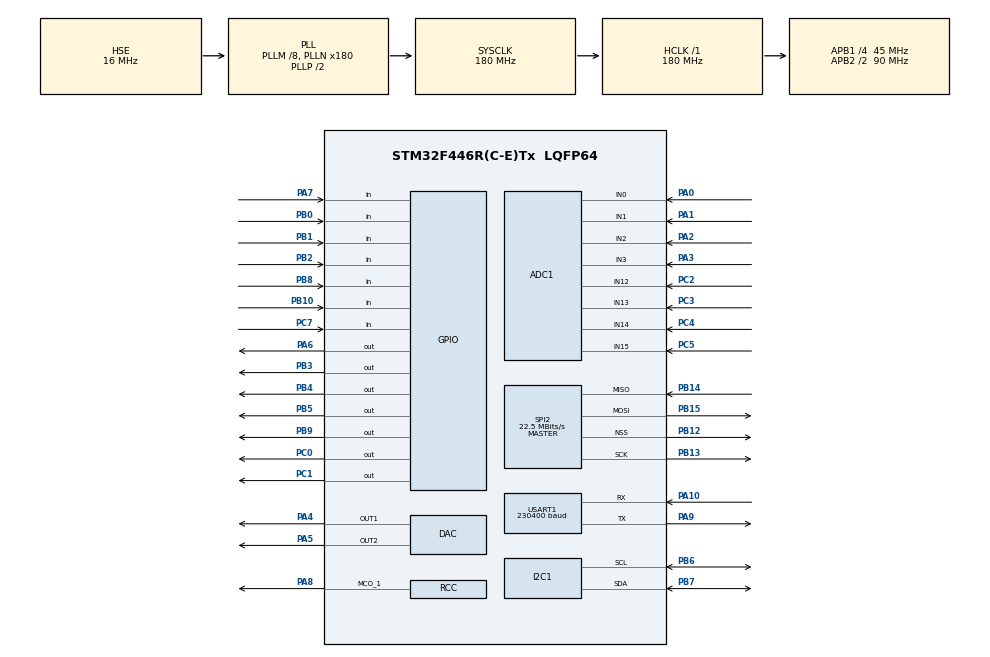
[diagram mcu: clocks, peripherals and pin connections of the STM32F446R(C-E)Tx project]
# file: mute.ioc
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ADC1.Channel-0\#ChannelRegularConversion=ADC_CHANNEL_0
ADC1.Channel-1\#ChannelRegularConversion=ADC_CHANNEL_1
ADC1.Channel-2\#ChannelRegularConversion=ADC_CHANNEL_2
ADC1.Channel-3\#ChannelRegularConversion=ADC_CHANNEL_3
ADC1.Channel-4\#ChannelRegularConversion=ADC_CHANNEL_12
ADC1.Channel-5\#ChannelRegularConversion=ADC_CHANNEL_13
ADC1.Channel-6\#ChannelRegularConversion=ADC_CHANNEL_14
ADC1.Channel-7\#ChannelRegularConversion=ADC_CHANNEL_15
ADC1.ClockPrescaler=ADC_CLOCK_SYNC_PCLK_DIV4
ADC1.ContinuousConvMode=ENABLE
ADC1.DMAContinuousRequests=ENABLE
ADC1.DiscontinuousConvMode=DISABLE
ADC1.EOCSelection=ADC_EOC_SEQ_CONV
ADC1.NbrOfConversion=8
ADC1.NbrOfConversionFlag=1
ADC1.Rank-0\#ChannelRegularConversion=1
ADC1.Rank-1\#ChannelRegularConversion=2
ADC1.Rank-2\#ChannelRegularConversion=3
ADC1.Rank-3\#ChannelRegularConversion=4
ADC1.Rank-4\#ChannelRegularConversion=5
ADC1.Rank-5\#ChannelRegularConversion=6
ADC1.Rank-6\#ChannelRegularConversion=7
ADC1.Rank-7\#ChannelRegularConversion=8
ADC1.SamplingTime-0\#ChannelRegularConversion=ADC_SAMPLETIME_144CYCLES
ADC1.SamplingTime-1\#ChannelRegularConversion=ADC_SAMPLETIME_144CYCLES
ADC1.SamplingTime-2\#ChannelRegularConversion=ADC_SAMPLETIME_144CYCLES
ADC1.SamplingTime-3\#ChannelRegularConversion=ADC_SAMPLETIME_144CYCLES
ADC1.SamplingTime-4\#ChannelRegularConversion=ADC_SAMPLETIME_144CYCLES
ADC1.SamplingTime-5\#ChannelRegularConversion=ADC_SAMPLETIME_144CYCLES
ADC1.SamplingTime-6\#ChannelRegularConversion=ADC_SAMPLETIME_144CYCLES
ADC1.SamplingTime-7\#ChannelRegularConversion=ADC_SAMPLETIME_144CYCLES
ADC1.ScanConvMode=ENABLE
ADC1.master=1
AwesomeAudioApparatus.Demiurge.0.4.4.AudioJjDemiurge=true
AwesomeAudioApparatus.Demiurge.0.4.4.BoardOoSupportJjDemiurge1JjRevG=true
AwesomeAudioApparatus.Demiurge.0.4.4.DeviceJjApplication=SDK
Dma.ADC1.0.Direction=DMA_PERIPH_TO_MEMORY
Dma.ADC1.0.FIFOMode=DMA_FIFOMODE_DISABLE
Dma.ADC1.0.Instance=DMA2_Stream0
Dma.ADC1.0.MemDataAlignment=DMA_MDATAALIGN_HALFWORD
Dma.ADC1.0.MemInc=DMA_MINC_ENABLE
Dma.ADC1.0.Mode=DMA_CIRCULAR
Dma.ADC1.0.PeriphDataAlignment=DMA_PDATAALIGN_HALFWORD
Dma.ADC1.0.PeriphInc=DMA_PINC_DISABLE
Dma.ADC1.0.Priority=DMA_PRIORITY_MEDIUM
Dma.I2C1_TX.1.Direction=DMA_MEMORY_TO_PERIPH
Dma.I2C1_TX.1.FIFOMode=DMA_FIFOMODE_DISABLE
Dma.I2C1_TX.1.Instance=DMA1_Stream6
Dma.I2C1_TX.1.MemDataAlignment=DMA_MDATAALIGN_BYTE
Dma.I2C1_TX.1.MemInc=DMA_MINC_ENABLE
Dma.I2C1_TX.1.Mode=DMA_NORMAL
Dma.I2C1_TX.1.PeriphDataAlignment=DMA_PDATAALIGN_BYTE
Dma.I2C1_TX.1.PeriphInc=DMA_PINC_DISABLE
Dma.I2C1_TX.1.Priority=DMA_PRIORITY_LOW
Dma.Request0=ADC1
Dma.Request1=I2C1_TX
Mcu.Family=STM32F4
Mcu.Name=STM32F446R(C-E)Tx
Mcu.Package=LQFP64
NVIC.DMA1_Stream6_IRQn=true\:0\:0\:false\:false\:true\:true\:true\:true
NVIC.I2C1_EV_IRQn=true\:0\:0\:false\:false\:true\:true\:true\:true
NVIC.PriorityGroup=NVIC_PRIORITYGROUP_4
NVIC.TIM3_IRQn=true\:15\:0\:true\:false\:true\:true\:true\:true
PA0-WKUP.Signal=ADCx_IN0
PA1.Signal=ADCx_IN1
PA10.Mode=Asynchronous
PA10.Signal=USART1_RX
PA11.Signal=USB_OTG_FS_DM
PA12.Signal=USB_OTG_FS_DP
PA13.Mode=Serial_Wire
PA13.Signal=SYS_JTMS-SWDIO
PA14.Mode=Serial_Wire
PA14.Signal=SYS_JTCK-SWCLK
PA2.Signal=ADCx_IN2
PA3.Signal=ADCx_IN3
PA4.Signal=COMP_DAC1_group
PA5.Signal=COMP_DAC2_group
PA6.Signal=GPIO_Output
PA7.Signal=GPIO_Input
PA8.Mode=Clock-out-1
PA8.Signal=RCC_MCO_1
PA9.Mode=Asynchronous
PA9.Signal=USART1_TX
PB0.Signal=GPIO_Input
PB1.Signal=GPIO_Input
PB10.Signal=GPIO_Input
PB12.Mode=NSS_Signal_Hard_Output
PB12.Signal=SPI2_NSS
PB13.Mode=Full_Duplex_Master
PB13.Signal=SPI2_SCK
PB14.Mode=Full_Duplex_Master
PB14.Signal=SPI2_MISO
PB15.Mode=Full_Duplex_Master
PB15.Signal=SPI2_MOSI
PB2.Signal=GPIO_Input
PB3.Signal=GPIO_Output
PB4.Signal=GPIO_Output
PB5.Signal=GPIO_Output
PB6.Mode=I2C
PB6.Signal=I2C1_SCL
PB7.Mode=I2C
PB7.Signal=I2C1_SDA
PB8.Signal=GPIO_Input
PB9.PinState=GPIO_PIN_RESET
PB9.Signal=GPIO_Output
PC0.Signal=GPIO_Output
PC1.Signal=GPIO_Output
PC10.Signal=SDIO_D2
PC11.Signal=SDIO_D3
PC12.Signal=SDIO_CK
PC2.Signal=ADCx_IN12
PC3.Signal=ADCx_IN13
PC4.Signal=ADCx_IN14
PC5.Signal=ADCx_IN15
PC7.Signal=GPIO_Input
PC8.Signal=SDIO_D0
PC9.Signal=SDIO_D1
PD2.Signal=SDIO_CMD
PH0-OSC_IN.Mode=HSE-External-Oscillator
PH0-OSC_IN.Signal=RCC_OSC_IN
PH1-OSC_OUT.Mode=HSE-External-Oscillator
PH1-OSC_OUT.Signal=RCC_OSC_OUT
ProjectManager.HeapSize=0x200
ProjectManager.StackSize=0x400
ProjectManager.TargetToolchain=STM32CubeIDE
RCC.AHBFreq_Value=180000000
RCC.APB1CLKDivider=RCC_HCLK_DIV4
RCC.APB1Freq_Value=45000000
RCC.APB1TimFreq_Value=90000000
RCC.APB2CLKDivider=RCC_HCLK_DIV2
RCC.APB2Freq_Value=90000000
RCC.APB2TimFreq_Value=180000000
RCC.CortexFreq_Value=180000000
RCC.HCLKFreq_Value=180000000
RCC.HSE_Timout=200
RCC.HSE_VALUE=16000000
RCC.PLLM=8
RCC.PLLN=180
RCC.PLLQ=8
RCC.PLLSourceVirtual=RCC_PLLSOURCE_HSE
RCC.RCC_MCO1Source=RCC_MCO1SOURCE_HSE
RCC.SYSCLKFreq_VALUE=180000000
RCC.SYSCLKSource=RCC_SYSCLKSOURCE_PLLCLK
RCC.USBFreq_Value=45000000
RCC.VCOOutputFreq_Value=360000000
SH.ADCx_IN0.0=ADC1_IN0,IN0
SH.ADCx_IN1.0=ADC1_IN1,IN1
SH.ADCx_IN12.0=ADC1_IN12,IN12
SH.ADCx_IN13.0=ADC1_IN13,IN13
SH.ADCx_IN14.0=ADC1_IN14,IN14
SH.ADCx_IN15.0=ADC1_IN15,IN15
SH.ADCx_IN2.0=ADC1_IN2,IN2
SH.ADCx_IN3.0=ADC1_IN3,IN3
SH.COMP_DAC1_group.0=DAC_OUT1,DAC_OUT1
SH.COMP_DAC2_group.0=DAC_OUT2,DAC_OUT2
SPI2.BaudRatePrescaler=SPI_BAUDRATEPRESCALER_2
SPI2.CalculateBaudRate=22.5 MBits/s
SPI2.Direction=SPI_DIRECTION_2LINES
SPI2.Mode=SPI_MODE_MASTER
SPI2.VirtualNSS=VM_NSSHARD
SPI2.VirtualType=VM_MASTER
TIM3.AutoReloadPreload=TIM_AUTORELOAD_PRELOAD_ENABLE
TIM3.CounterMode=TIM_COUNTERMODE_DOWN
TIM3.Period=3750
USART1.BaudRate=230400
USART1.VirtualMode=VM_ASYNC
VP_AwesomeAudioApparatus.Demiurge_VS_AudioJjDemiurge_0.4.1_0.4.4.Mode=AudioJjDemiurge
VP_AwesomeAudioApparatus.Demiurge_VS_BoardOoSupportJjDemiurge1_0.4.1_0.4.4.Mode=BoardOoSupportJjDemiurge1
VP_AwesomeAudioApparatus.Demiurge_VS_DeviceJjApplication_0.4.0_0.4.4.Mode=DeviceJjApplication
VP_TIM3_VS_ClockSourceINT.Mode=Internal
board=custom

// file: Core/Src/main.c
/* USER CODE BEGIN Header */
/*
  Copyright 2019-2022, Awesome Audio Apparatus.

Licensed under the Apache License, Version 2.0 (the "License");
you may not use this file except in compliance with the License.
You may obtain a copy of the License at

      https://www.apache.org/licenses/LICENSE-2.0

Unless required by applicable law or agreed to in writing, software
distributed under the License is distributed on an "AS IS" BASIS,
WITHOUT WARRANTIES OR CONDITIONS OF ANY KIND, either express or implied.
See the License for the specific language governing permissions and
      limitations under the License.
*/
/* USER CODE END Header */
#include "main.h"

/* USER CODE BEGIN Includes */
#include "demiurge.h"
/* USER CODE END Includes */

ADC_HandleTypeDef hadc1;
DMA_HandleTypeDef hdma_adc1;

DAC_HandleTypeDef hdac;

I2C_HandleTypeDef hi2c1;
DMA_HandleTypeDef hdma_i2c1_tx;

SPI_HandleTypeDef hspi2;

TIM_HandleTypeDef htim3;

UART_HandleTypeDef huart1;

void SystemClock_Config(void);
static void MX_GPIO_Init(void);
static void MX_DMA_Init(void);
static void MX_ADC1_Init(void);
static void MX_DAC_Init(void);
static void MX_TIM3_Init(void);
static void MX_I2C1_Init(void);
static void MX_SPI2_Init(void);
static void MX_USART1_UART_Init(void);

int main(void)
{

  /* MCU Configuration--------------------------------------------------------*/

  /* Reset of all peripherals, Initializes the Flash interface and the Systick. */
  HAL_Init();

  /* Configure the system clock */
  SystemClock_Config();

  /* Initialize all configured peripherals */
  MX_GPIO_Init();
  MX_DMA_Init();
  MX_ADC1_Init();
  MX_DAC_Init();
  MX_TIM3_Init();
  MX_I2C1_Init();
  MX_SPI2_Init();
  MX_USART1_UART_Init();
  MX_User_Init();

  /* Infinite loop */
  while (1)
  {

  MX_User_Process();
  }
}

void SystemClock_Config(void)
{
  RCC_OscInitTypeDef RCC_OscInitStruct = {0};
  RCC_ClkInitTypeDef RCC_ClkInitStruct = {0};

  /** Configure the main internal regulator output voltage
  */
  __HAL_RCC_PWR_CLK_ENABLE();
  __HAL_PWR_VOLTAGESCALING_CONFIG(PWR_REGULATOR_VOLTAGE_SCALE1);

  /** Initializes the RCC Oscillators according to the specified parameters
  * in the RCC_OscInitTypeDef structure.
  */
  RCC_OscInitStruct.OscillatorType = RCC_OSCILLATORTYPE_HSE;
  RCC_OscInitStruct.HSEState = RCC_HSE_ON;
  RCC_OscInitStruct.PLL.PLLState = RCC_PLL_ON;
  RCC_OscInitStruct.PLL.PLLSource = RCC_PLLSOURCE_HSE;
  RCC_OscInitStruct.PLL.PLLM = 8;
  RCC_OscInitStruct.PLL.PLLN = 180;
  RCC_OscInitStruct.PLL.PLLP = RCC_PLLP_DIV2;
  RCC_OscInitStruct.PLL.PLLQ = 8;
  RCC_OscInitStruct.PLL.PLLR = 2;
  if (HAL_RCC_OscConfig(&RCC_OscInitStruct) != HAL_OK)
  {
    Error_Handler();
  }

  /** Activate the Over-Drive mode
  */
  if (HAL_PWREx_EnableOverDrive() != HAL_OK)
  {
    Error_Handler();
  }

  /** Initializes the CPU, AHB and APB buses clocks
  */
  RCC_ClkInitStruct.ClockType = RCC_CLOCKTYPE_HCLK|RCC_CLOCKTYPE_SYSCLK
                              |RCC_CLOCKTYPE_PCLK1|RCC_CLOCKTYPE_PCLK2;
  RCC_ClkInitStruct.SYSCLKSource = RCC_SYSCLKSOURCE_PLLCLK;
  RCC_ClkInitStruct.AHBCLKDivider = RCC_SYSCLK_DIV1;
  RCC_ClkInitStruct.APB1CLKDivider = RCC_HCLK_DIV4;
  RCC_ClkInitStruct.APB2CLKDivider = RCC_HCLK_DIV2;

  if (HAL_RCC_ClockConfig(&RCC_ClkInitStruct, FLASH_LATENCY_5) != HAL_OK)
  {
    Error_Handler();
  }
  HAL_RCC_MCOConfig(RCC_MCO1, RCC_MCO1SOURCE_HSE, RCC_MCODIV_1);
}

static void MX_ADC1_Init(void)
{

  ADC_ChannelConfTypeDef sConfig = {0};

  /** Configure the global features of the ADC (Clock, Resolution, Data Alignment and number of conversion)
  */
  hadc1.Instance = ADC1;
  hadc1.Init.ClockPrescaler = ADC_CLOCK_SYNC_PCLK_DIV4;
  hadc1.Init.Resolution = ADC_RESOLUTION_12B;
  hadc1.Init.ScanConvMode = ENABLE;
  hadc1.Init.ContinuousConvMode = ENABLE;
  hadc1.Init.DiscontinuousConvMode = DISABLE;
  hadc1.Init.ExternalTrigConvEdge = ADC_EXTERNALTRIGCONVEDGE_NONE;
  hadc1.Init.ExternalTrigConv = ADC_SOFTWARE_START;
  hadc1.Init.DataAlign = ADC_DATAALIGN_RIGHT;
  hadc1.Init.NbrOfConversion = 8;
  hadc1.Init.DMAContinuousRequests = ENABLE;
  hadc1.Init.EOCSelection = ADC_EOC_SEQ_CONV;
  if (HAL_ADC_Init(&hadc1) != HAL_OK)
  {
    Error_Handler();
  }

  /** Configure for the selected ADC regular channel its corresponding rank in the sequencer and its sample time.
  */
  sConfig.Channel = ADC_CHANNEL_0;
  sConfig.Rank = 1;
  sConfig.SamplingTime = ADC_SAMPLETIME_144CYCLES;
  if (HAL_ADC_ConfigChannel(&hadc1, &sConfig) != HAL_OK)
  {
    Error_Handler();
  }

  /** Configure for the selected ADC regular channel its corresponding rank in the sequencer and its sample time.
  */
  sConfig.Channel = ADC_CHANNEL_1;
  sConfig.Rank = 2;
  if (HAL_ADC_ConfigChannel(&hadc1, &sConfig) != HAL_OK)
  {
    Error_Handler();
  }

  /** Configure for the selected ADC regular channel its corresponding rank in the sequencer and its sample time.
  */
  sConfig.Channel = ADC_CHANNEL_2;
  sConfig.Rank = 3;
  if (HAL_ADC_ConfigChannel(&hadc1, &sConfig) != HAL_OK)
  {
    Error_Handler();
  }

  /** Configure for the selected ADC regular channel its corresponding rank in the sequencer and its sample time.
  */
  sConfig.Channel = ADC_CHANNEL_3;
  sConfig.Rank = 4;
  if (HAL_ADC_ConfigChannel(&hadc1, &sConfig) != HAL_OK)
  {
    Error_Handler();
  }

  /** Configure for the selected ADC regular channel its corresponding rank in the sequencer and its sample time.
  */
  sConfig.Channel = ADC_CHANNEL_12;
  sConfig.Rank = 5;
  if (HAL_ADC_ConfigChannel(&hadc1, &sConfig) != HAL_OK)
  {
    Error_Handler();
  }

  /** Configure for the selected ADC regular channel its corresponding rank in the sequencer and its sample time.
  */
  sConfig.Channel = ADC_CHANNEL_13;
  sConfig.Rank = 6;
  if (HAL_ADC_ConfigChannel(&hadc1, &sConfig) != HAL_OK)
  {
    Error_Handler();
  }

  /** Configure for the selected ADC regular channel its corresponding rank in the sequencer and its sample time.
  */
  sConfig.Channel = ADC_CHANNEL_14;
  sConfig.Rank = 7;
  if (HAL_ADC_ConfigChannel(&hadc1, &sConfig) != HAL_OK)
  {
    Error_Handler();
  }

  /** Configure for the selected ADC regular channel its corresponding rank in the sequencer and its sample time.
  */
  sConfig.Channel = ADC_CHANNEL_15;
  sConfig.Rank = 8;
  if (HAL_ADC_ConfigChannel(&hadc1, &sConfig) != HAL_OK)
  {
    Error_Handler();
  }

}

static void MX_DAC_Init(void)
{

  DAC_ChannelConfTypeDef sConfig = {0};

  /** DAC Initialization
  */
  hdac.Instance = DAC;
  if (HAL_DAC_Init(&hdac) != HAL_OK)
  {
    Error_Handler();
  }

  /** DAC channel OUT1 config
  */
  sConfig.DAC_Trigger = DAC_TRIGGER_NONE;
  sConfig.DAC_OutputBuffer = DAC_OUTPUTBUFFER_ENABLE;
  if (HAL_DAC_ConfigChannel(&hdac, &sConfig, DAC_CHANNEL_1) != HAL_OK)
  {
    Error_Handler();
  }

  /** DAC channel OUT2 config
  */
  if (HAL_DAC_ConfigChannel(&hdac, &sConfig, DAC_CHANNEL_2) != HAL_OK)
  {
    Error_Handler();
  }

}

static void MX_I2C1_Init(void)
{

  hi2c1.Instance = I2C1;
  hi2c1.Init.ClockSpeed = 100000;
  hi2c1.Init.DutyCycle = I2C_DUTYCYCLE_2;
  hi2c1.Init.OwnAddress1 = 0;
  hi2c1.Init.AddressingMode = I2C_ADDRESSINGMODE_7BIT;
  hi2c1.Init.DualAddressMode = I2C_DUALADDRESS_DISABLE;
  hi2c1.Init.OwnAddress2 = 0;
  hi2c1.Init.GeneralCallMode = I2C_GENERALCALL_DISABLE;
  hi2c1.Init.NoStretchMode = I2C_NOSTRETCH_DISABLE;
  if (HAL_I2C_Init(&hi2c1) != HAL_OK)
  {
    Error_Handler();
  }

}

static void MX_SPI2_Init(void)
{

  /* SPI2 parameter configuration*/
  hspi2.Instance = SPI2;
  hspi2.Init.Mode = SPI_MODE_MASTER;
  hspi2.Init.Direction = SPI_DIRECTION_2LINES;
  hspi2.Init.DataSize = SPI_DATASIZE_8BIT;
  hspi2.Init.CLKPolarity = SPI_POLARITY_LOW;
  hspi2.Init.CLKPhase = SPI_PHASE_1EDGE;
  hspi2.Init.NSS = SPI_NSS_HARD_OUTPUT;
  hspi2.Init.BaudRatePrescaler = SPI_BAUDRATEPRESCALER_2;
  hspi2.Init.FirstBit = SPI_FIRSTBIT_MSB;
  hspi2.Init.TIMode = SPI_TIMODE_DISABLE;
  hspi2.Init.CRCCalculation = SPI_CRCCALCULATION_DISABLE;
  hspi2.Init.CRCPolynomial = 10;
  if (HAL_SPI_Init(&hspi2) != HAL_OK)
  {
    Error_Handler();
  }

}

static void MX_TIM3_Init(void)
{

  TIM_ClockConfigTypeDef sClockSourceConfig = {0};
  TIM_MasterConfigTypeDef sMasterConfig = {0};

  htim3.Instance = TIM3;
  htim3.Init.Prescaler = 0;
  htim3.Init.CounterMode = TIM_COUNTERMODE_DOWN;
  htim3.Init.Period = 3750;
  htim3.Init.ClockDivision = TIM_CLOCKDIVISION_DIV1;
  htim3.Init.AutoReloadPreload = TIM_AUTORELOAD_PRELOAD_ENABLE;
  if (HAL_TIM_Base_Init(&htim3) != HAL_OK)
  {
    Error_Handler();
  }
  sClockSourceConfig.ClockSource = TIM_CLOCKSOURCE_INTERNAL;
  if (HAL_TIM_ConfigClockSource(&htim3, &sClockSourceConfig) != HAL_OK)
  {
    Error_Handler();
  }
  sMasterConfig.MasterOutputTrigger = TIM_TRGO_RESET;
  sMasterConfig.MasterSlaveMode = TIM_MASTERSLAVEMODE_DISABLE;
  if (HAL_TIMEx_MasterConfigSynchronization(&htim3, &sMasterConfig) != HAL_OK)
  {
    Error_Handler();
  }

}

static void MX_USART1_UART_Init(void)
{

  huart1.Instance = USART1;
  huart1.Init.BaudRate = 230400;
  huart1.Init.WordLength = UART_WORDLENGTH_8B;
  huart1.Init.StopBits = UART_STOPBITS_1;
  huart1.Init.Parity = UART_PARITY_NONE;
  huart1.Init.Mode = UART_MODE_TX_RX;
  huart1.Init.HwFlowCtl = UART_HWCONTROL_NONE;
  huart1.Init.OverSampling = UART_OVERSAMPLING_16;
  if (HAL_UART_Init(&huart1) != HAL_OK)
  {
    Error_Handler();
  }

}

static void MX_DMA_Init(void)
{

  /* DMA controller clock enable */
  __HAL_RCC_DMA2_CLK_ENABLE();
  __HAL_RCC_DMA1_CLK_ENABLE();

  /* DMA interrupt init */
  /* DMA1_Stream6_IRQn interrupt configuration */
  HAL_NVIC_SetPriority(DMA1_Stream6_IRQn, 0, 0);
  HAL_NVIC_EnableIRQ(DMA1_Stream6_IRQn);

}

static void MX_GPIO_Init(void)
{
  GPIO_InitTypeDef GPIO_InitStruct = {0};

  /* GPIO Ports Clock Enable */
  __HAL_RCC_GPIOH_CLK_ENABLE();
  __HAL_RCC_GPIOC_CLK_ENABLE();
  __HAL_RCC_GPIOA_CLK_ENABLE();
  __HAL_RCC_GPIOB_CLK_ENABLE();
  __HAL_RCC_GPIOD_CLK_ENABLE();

  /*Configure GPIO pin Output Level */
  HAL_GPIO_WritePin(GPIOC, GPIO_PIN_0|GPIO_PIN_1, GPIO_PIN_RESET);

  /*Configure GPIO pin Output Level */
  HAL_GPIO_WritePin(GPIOA, GPIO_PIN_6, GPIO_PIN_RESET);

  /*Configure GPIO pin Output Level */
  HAL_GPIO_WritePin(GPIOB, GPIO_PIN_3|GPIO_PIN_4|GPIO_PIN_5|GPIO_PIN_9, GPIO_PIN_RESET);

  /*Configure GPIO pins : PC0 PC1 */
  GPIO_InitStruct.Pin = GPIO_PIN_0|GPIO_PIN_1;
  GPIO_InitStruct.Mode = GPIO_MODE_OUTPUT_PP;
  GPIO_InitStruct.Pull = GPIO_NOPULL;
  GPIO_InitStruct.Speed = GPIO_SPEED_FREQ_LOW;
  HAL_GPIO_Init(GPIOC, &GPIO_InitStruct);

  /*Configure GPIO pin : PA6 */
  GPIO_InitStruct.Pin = GPIO_PIN_6;
  GPIO_InitStruct.Mode = GPIO_MODE_OUTPUT_PP;
  GPIO_InitStruct.Pull = GPIO_NOPULL;
  GPIO_InitStruct.Speed = GPIO_SPEED_FREQ_LOW;
  HAL_GPIO_Init(GPIOA, &GPIO_InitStruct);

  /*Configure GPIO pin : PA7 */
  GPIO_InitStruct.Pin = GPIO_PIN_7;
  GPIO_InitStruct.Mode = GPIO_MODE_INPUT;
  GPIO_InitStruct.Pull = GPIO_NOPULL;
  HAL_GPIO_Init(GPIOA, &GPIO_InitStruct);

  /*Configure GPIO pins : PB0 PB1 PB2 PB10
                           PB8 */
  GPIO_InitStruct.Pin = GPIO_PIN_0|GPIO_PIN_1|GPIO_PIN_2|GPIO_PIN_10
                          |GPIO_PIN_8;
  GPIO_InitStruct.Mode = GPIO_MODE_INPUT;
  GPIO_InitStruct.Pull = GPIO_NOPULL;
  HAL_GPIO_Init(GPIOB, &GPIO_InitStruct);

  /*Configure GPIO pin : PC7 */
  GPIO_InitStruct.Pin = GPIO_PIN_7;
  GPIO_InitStruct.Mode = GPIO_MODE_INPUT;
  GPIO_InitStruct.Pull = GPIO_NOPULL;
  HAL_GPIO_Init(GPIOC, &GPIO_InitStruct);

  /*Configure GPIO pins : PC8 PC9 PC10 PC11
                           PC12 */
  GPIO_InitStruct.Pin = GPIO_PIN_8|GPIO_PIN_9|GPIO_PIN_10|GPIO_PIN_11
                          |GPIO_PIN_12;
  GPIO_InitStruct.Mode = GPIO_MODE_AF_PP;
  GPIO_InitStruct.Pull = GPIO_NOPULL;
  GPIO_InitStruct.Speed = GPIO_SPEED_FREQ_VERY_HIGH;
  GPIO_InitStruct.Alternate = GPIO_AF12_SDIO;
  HAL_GPIO_Init(GPIOC, &GPIO_InitStruct);

  /*Configure GPIO pin : PA8 */
  GPIO_InitStruct.Pin = GPIO_PIN_8;
  GPIO_InitStruct.Mode = GPIO_MODE_AF_PP;
  GPIO_InitStruct.Pull = GPIO_NOPULL;
  GPIO_InitStruct.Speed = GPIO_SPEED_FREQ_LOW;
  GPIO_InitStruct.Alternate = GPIO_AF0_MCO;
  HAL_GPIO_Init(GPIOA, &GPIO_InitStruct);

  /*Configure GPIO pins : PA11 PA12 */
  GPIO_InitStruct.Pin = GPIO_PIN_11|GPIO_PIN_12;
  GPIO_InitStruct.Mode = GPIO_MODE_AF_PP;
  GPIO_InitStruct.Pull = GPIO_NOPULL;
  GPIO_InitStruct.Speed = GPIO_SPEED_FREQ_VERY_HIGH;
  GPIO_InitStruct.Alternate = GPIO_AF10_OTG_FS;
  HAL_GPIO_Init(GPIOA, &GPIO_InitStruct);

  /*Configure GPIO pin : PD2 */
  GPIO_InitStruct.Pin = GPIO_PIN_2;
  GPIO_InitStruct.Mode = GPIO_MODE_AF_PP;
  GPIO_InitStruct.Pull = GPIO_NOPULL;
  GPIO_InitStruct.Speed = GPIO_SPEED_FREQ_VERY_HIGH;
  GPIO_InitStruct.Alternate = GPIO_AF12_SDIO;
  HAL_GPIO_Init(GPIOD, &GPIO_InitStruct);

  /*Configure GPIO pins : PB3 PB4 PB5 PB9 */
  GPIO_InitStruct.Pin = GPIO_PIN_3|GPIO_PIN_4|GPIO_PIN_5|GPIO_PIN_9;
  GPIO_InitStruct.Mode = GPIO_MODE_OUTPUT_PP;
  GPIO_InitStruct.Pull = GPIO_NOPULL;
  GPIO_InitStruct.Speed = GPIO_SPEED_FREQ_LOW;
  HAL_GPIO_Init(GPIOB, &GPIO_InitStruct);

}

void Error_Handler(void)
{
  __disable_irq();
  while (1)
  {
  }
}
